VERSION ""

NS_ :

BS_:

BU_: EV EVCC

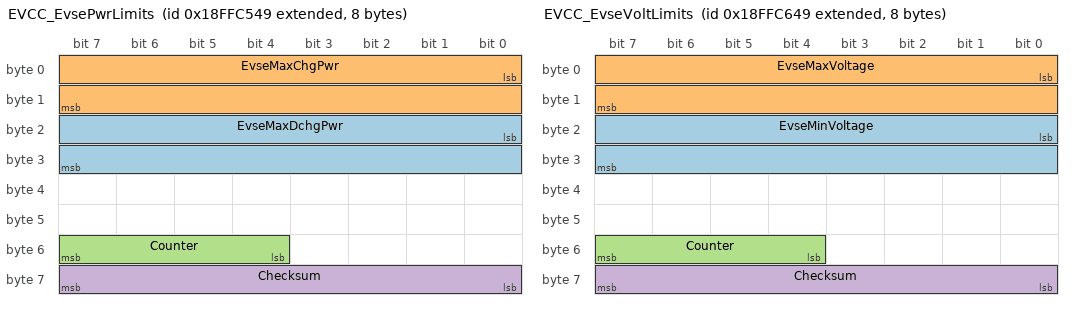
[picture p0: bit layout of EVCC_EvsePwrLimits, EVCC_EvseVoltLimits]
BO_ 2566899017 EVCC_EvsePwrLimits: 8 EVCC
 SG_ EvseMaxDchgPwr : 16|16@1+ (0.5,0) [0|32127.5] "kW"  EV
 SG_ EvseMaxChgPwr : 0|16@1+ (0.5,0) [0|32127.5] "kW"  EV
 SG_ Counter : 52|4@1+ (1,0) [0|0] ""  EV
 SG_ Checksum : 56|8@1+ (1,0) [0|255] "NU"  EV

BO_ 2566899273 EVCC_EvseVoltLimits: 8 EVCC
 SG_ EvseMinVoltage : 16|16@1+ (0.125,0) [0|8031.875] "V"  EV
 SG_ EvseMaxVoltage : 0|16@1+ (0.125,0) [0|8031.875] "V"  EV
 SG_ Counter : 52|4@1+ (1,0) [0|0] ""  EV
 SG_ Checksum : 56|8@1+ (1,0) [0|255] "NU"  EV

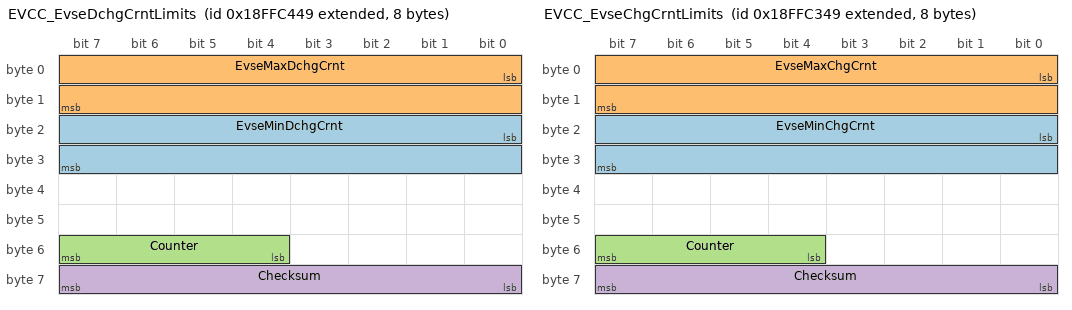
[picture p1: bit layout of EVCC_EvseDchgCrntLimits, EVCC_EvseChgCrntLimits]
BO_ 2566898761 EVCC_EvseDchgCrntLimits: 8 EVCC
 SG_ EvseMinDchgCrnt : 16|16@1+ (0.125,0) [0|8031.875] "A"  EV
 SG_ EvseMaxDchgCrnt : 0|16@1+ (0.125,0) [0|8031.875] "A"  EV
 SG_ Counter : 52|4@1+ (1,0) [0|0] ""  EV
 SG_ Checksum : 56|8@1+ (1,0) [0|255] "NU"  EV

BO_ 2566898505 EVCC_EvseChgCrntLimits: 8 EVCC
 SG_ EvseMinChgCrnt : 16|16@1+ (0.125,0) [0|8031.875] "A"  EV
 SG_ EvseMaxChgCrnt : 0|16@1+ (0.125,0) [0|8031.875] "A"  EV
 SG_ Counter : 52|4@1+ (1,0) [0|0] ""  EV
 SG_ Checksum : 56|8@1+ (1,0) [0|255] "NU"  EV

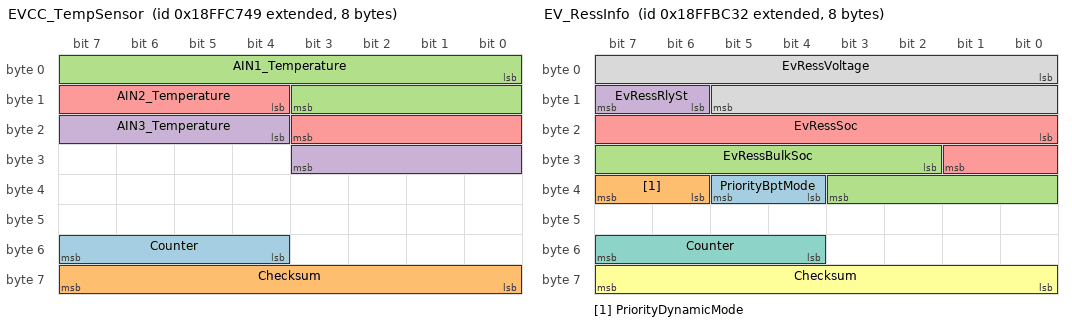
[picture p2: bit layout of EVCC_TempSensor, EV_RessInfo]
BO_ 2566899529 EVCC_TempSensor: 8 EVCC
 SG_ Counter : 52|4@1+ (1,0) [0|0] ""  EV
 SG_ Checksum : 56|8@1+ (1,0) [0|255] "NU"  EV
 SG_ AIN1_Temperature : 0|12@1+ (1,-40) [-40|4000] "degC_or_Ohm"  EV
 SG_ AIN3_Temperature : 20|8@1+ (1,-40) [-40|210] "degC"  EV
 SG_ AIN2_Temperature : 12|8@1+ (1,-40) [-40|210] "degC"  EV

BO_ 2566896690 EV_RessInfo: 8 EV
 SG_ PriorityBptMode : 36|2@1+ (1,0) [0|3] ""  EVCC
 SG_ PriorityDynamicMode : 38|2@1+ (1,0) [0|3] ""  EVCC
 SG_ EvRessBulkSoc : 26|10@1+ (0.1,0) [0|100] "%"  EVCC
 SG_ EvRessRlySt : 14|2@1+ (1,0) [0|3] "bool"  EVCC
 SG_ EvRessSoc : 16|10@1+ (0.1,0) [0|100] "%"  EVCC
 SG_ Checksum : 56|8@1+ (1,0) [0|255] "NU"  EVCC
 SG_ Counter : 52|4@1+ (1,0) [0|0] ""  EVCC
 SG_ EvRessVoltage : 0|14@1+ (0.1,0) [0|1638.3] "V"  EVCC

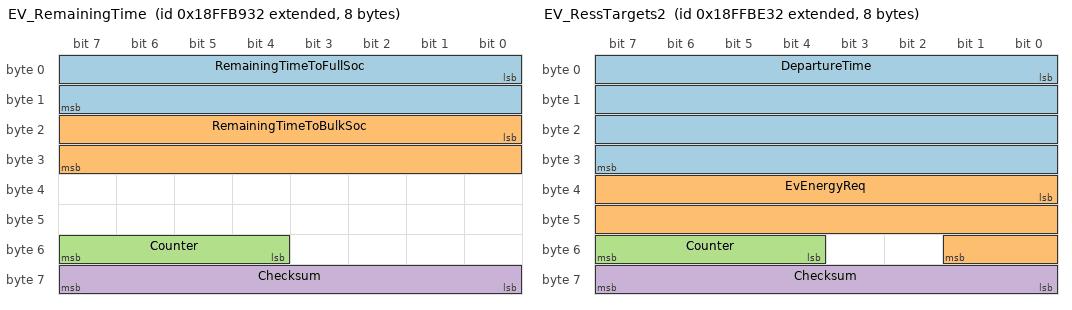
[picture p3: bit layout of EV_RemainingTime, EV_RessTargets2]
BO_ 2566895922 EV_RemainingTime: 8 EV
 SG_ RemainingTimeToFullSoc : 0|16@1+ (5,0) [0|327675] "s"  EVCC
 SG_ RemainingTimeToBulkSoc : 16|16@1+ (5,0) [0|327675] "s"  EVCC
 SG_ Counter : 52|4@1+ (1,0) [0|0] ""  EVCC
 SG_ Checksum : 56|8@1+ (1,0) [0|255] "NU"  EVCC

BO_ 2566897202 EV_RessTargets2: 8 EV
 SG_ DepartureTime : 0|32@1+ (1,0) [0|4294967295] "s"  EVCC
 SG_ EvEnergyReq : 32|18@1- (0.5,0) [-65536|65535.5] "kWh"  EVCC
 SG_ Counter : 52|4@1+ (1,0) [0|0] ""  EVCC
 SG_ Checksum : 56|8@1+ (1,0) [0|255] "NU"  EVCC

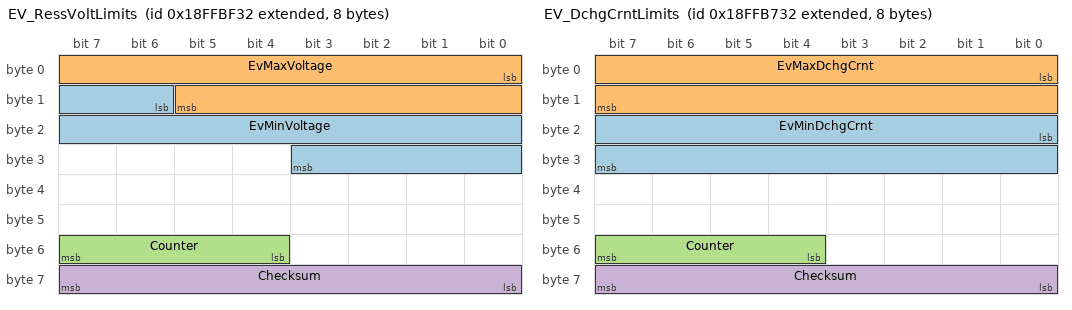
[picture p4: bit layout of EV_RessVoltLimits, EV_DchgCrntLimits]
BO_ 2566897458 EV_RessVoltLimits: 8 EV
 SG_ EvMinVoltage : 14|14@1+ (0.1,0) [0|1638.3] "V"  EVCC
 SG_ EvMaxVoltage : 0|14@1+ (0.1,0) [0|1638.3] "V"  EVCC
 SG_ Counter : 52|4@1+ (1,0) [0|0] ""  EVCC
 SG_ Checksum : 56|8@1+ (1,0) [0|255] "NU"  EVCC

BO_ 2566895410 EV_DchgCrntLimits: 8 EV
 SG_ EvMinDchgCrnt : 16|16@1- (0.1,0) [-3276.8|3276.7] "A"  EVCC
 SG_ EvMaxDchgCrnt : 0|16@1- (0.1,0) [-3276.8|3276.7] "A"  EVCC
 SG_ Counter : 52|4@1+ (1,0) [0|0] ""  EVCC
 SG_ Checksum : 56|8@1+ (1,0) [0|255] "NU"  EVCC

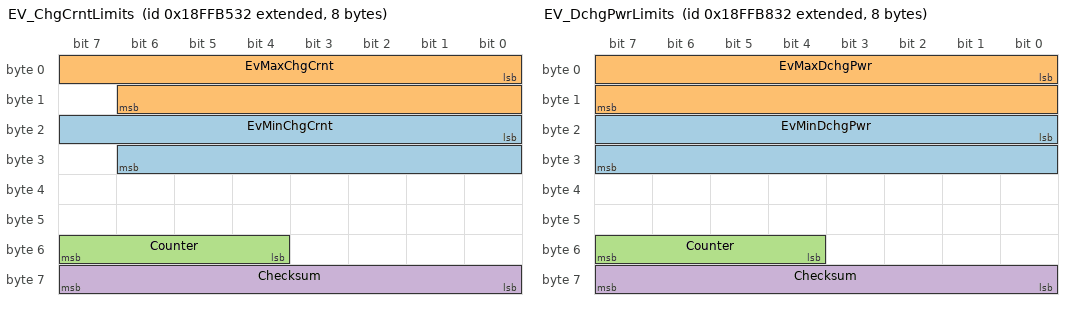
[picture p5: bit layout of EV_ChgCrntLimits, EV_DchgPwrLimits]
BO_ 2566894898 EV_ChgCrntLimits: 8 EV
 SG_ EvMinChgCrnt : 16|15@1+ (0.1,0) [0|3276.7] "A"  EVCC
 SG_ EvMaxChgCrnt : 0|15@1+ (0.1,0) [0|3276.7] "A"  EVCC
 SG_ Counter : 52|4@1+ (1,0) [0|0] ""  EVCC
 SG_ Checksum : 56|8@1+ (1,0) [0|255] "NU"  EVCC

BO_ 2566895666 EV_DchgPwrLimits: 8 EV
 SG_ EvMinDchgPwr : 16|16@1- (0.1,0) [-3276.8|3276.7] "kW"  EVCC
 SG_ EvMaxDchgPwr : 0|16@1- (0.1,0) [-3276.8|3276.7] "kW"  EVCC
 SG_ Counter : 52|4@1+ (1,0) [0|0] ""  EVCC
 SG_ Checksum : 56|8@1+ (1,0) [0|255] "NU"  EVCC

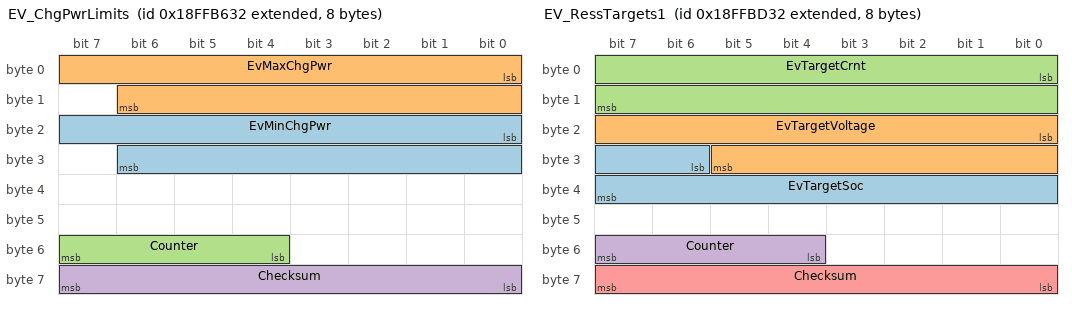
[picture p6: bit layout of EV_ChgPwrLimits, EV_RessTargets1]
BO_ 2566895154 EV_ChgPwrLimits: 8 EV
 SG_ EvMinChgPwr : 16|15@1+ (0.1,0) [0|3276.7] "kW"  EVCC
 SG_ EvMaxChgPwr : 0|15@1+ (0.1,0) [0|3276.7] "kW"  EVCC
 SG_ Counter : 52|4@1+ (1,0) [0|0] ""  EVCC
 SG_ Checksum : 56|8@1+ (1,0) [0|255] "NU"  EVCC

BO_ 2566896946 EV_RessTargets1: 8 EV
 SG_ EvTargetSoc : 30|10@1+ (0.1,0) [0|100] "%"  EVCC
 SG_ EvTargetVoltage : 16|14@1+ (0.1,0) [0|1638.3] "V"  EVCC
 SG_ EvTargetCrnt : 0|16@1- (0.1,0) [-3276.8|3276.7] "A"  EVCC
 SG_ Counter : 52|4@1+ (1,0) [0|0] ""  EVCC
 SG_ Checksum : 56|8@1+ (1,0) [0|255] "NU"  EVCC

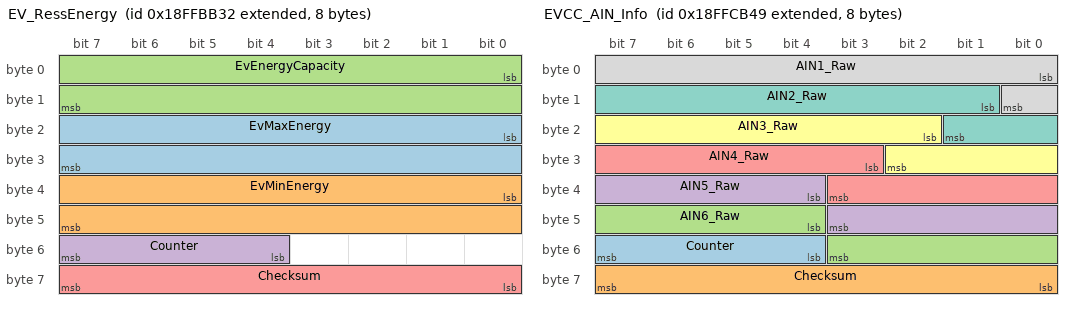
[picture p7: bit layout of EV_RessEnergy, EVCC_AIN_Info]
BO_ 2566896434 EV_RessEnergy: 8 EV
 SG_ EvMaxEnergy : 16|16@1+ (1,0) [0|65535] "kWh"  EVCC
 SG_ EvMinEnergy : 32|16@1+ (1,0) [0|65535] "kWh"  EVCC
 SG_ EvEnergyCapacity : 0|16@1+ (1,0) [0|65535] "kWh"  EVCC
 SG_ Counter : 52|4@1+ (1,0) [0|0] ""  EVCC
 SG_ Checksum : 56|8@1+ (1,0) [0|255] "NU"  EVCC

BO_ 2566900553 EVCC_AIN_Info: 8 EVCC
 SG_ Counter : 52|4@1+ (1,0) [0|0] ""  EV
 SG_ Checksum : 56|8@1+ (1,0) [0|255] "NU"  EV
 SG_ AIN6_Raw : 44|8@1+ (0.02,0) [0|5] "V"  EV
 SG_ AIN5_Raw : 36|8@1+ (0.02,0) [0|5] "V"  EV
 SG_ AIN4_Raw : 27|9@1+ (0.1,0) [0|32] "V"  EV
 SG_ AIN3_Raw : 18|9@1+ (0.01,0) [0|5] "V"  EV
 SG_ AIN2_Raw : 9|9@1+ (0.01,0) [0|5] "V"  EV
 SG_ AIN1_Raw : 0|9@1+ (0.01,0) [0|5] "V"  EV

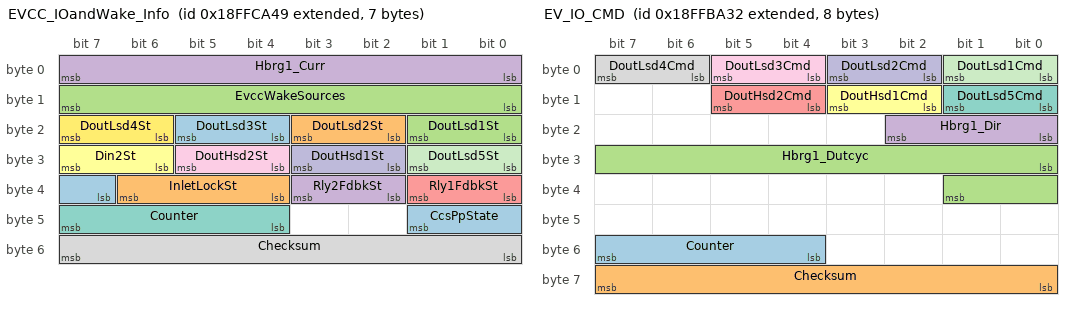
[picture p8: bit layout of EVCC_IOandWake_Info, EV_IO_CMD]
BO_ 2566900297 EVCC_IOandWake_Info: 7 EVCC
 SG_ CcsPpState : 39|3@1+ (1,0) [0|7] ""  EV
 SG_ InletLockSt : 36|3@1+ (1,0) [0|7] ""  EV
 SG_ EvccWakeSources : 8|8@1+ (1,0) [0|255] ""  EV
 SG_ Rly2FdbkSt : 34|2@1+ (1,0) [0|3] "NU"  EV
 SG_ Rly1FdbkSt : 32|2@1+ (1,0) [0|3] "NU"  EV
 SG_ Din2St : 30|2@1+ (1,0) [0|3] "NU"  EV
 SG_ Counter : 44|4@1+ (1,0) [0|0] ""  EV
 SG_ Checksum : 48|8@1+ (1,0) [0|255] "NU"  EV
 SG_ DoutHsd2St : 28|2@1+ (1,0) [0|3] "NU"  EV
 SG_ DoutHsd1St : 26|2@1+ (1,0) [0|3] "NU"  EV
 SG_ DoutLsd5St : 24|2@1+ (1,0) [0|3] "NU"  EV
 SG_ DoutLsd4St : 22|2@1+ (1,0) [0|3] "NU"  EV
 SG_ DoutLsd3St : 20|2@1+ (1,0) [0|3] "NU"  EV
 SG_ DoutLsd2St : 18|2@1+ (1,0) [0|3] "NU"  EV
 SG_ DoutLsd1St : 16|2@1+ (1,0) [0|3] "NU"  EV
 SG_ Hbrg1_Curr : 0|8@1+ (0.1,0) [0|21] "A"  EV

BO_ 2566896178 EV_IO_CMD: 8 EV
 SG_ Counter : 52|4@1+ (1,0) [0|0] ""  EVCC
 SG_ Checksum : 56|8@1+ (1,0) [0|255] "NU"  EVCC
 SG_ Hbrg1_Dutcyc : 24|10@1+ (0.1,0) [0|100] "%"  EVCC
 SG_ Hbrg1_Dir : 16|3@1+ (1,0) [0|7] "NU"  EVCC
 SG_ DoutHsd2Cmd : 12|2@1+ (1,0) [0|3] "bool"  EVCC
 SG_ DoutHsd1Cmd : 10|2@1+ (1,0) [0|3] "bool"  EVCC
 SG_ DoutLsd5Cmd : 8|2@1+ (1,0) [0|3] "bool"  EVCC
 SG_ DoutLsd4Cmd : 6|2@1+ (1,0) [0|3] "bool"  EVCC
 SG_ DoutLsd3Cmd : 4|2@1+ (1,0) [0|3] "bool"  EVCC
 SG_ DoutLsd2Cmd : 2|2@1+ (1,0) [0|3] "bool"  EVCC
 SG_ DoutLsd1Cmd : 0|2@1+ (1,0) [0|3] "bool"  EVCC

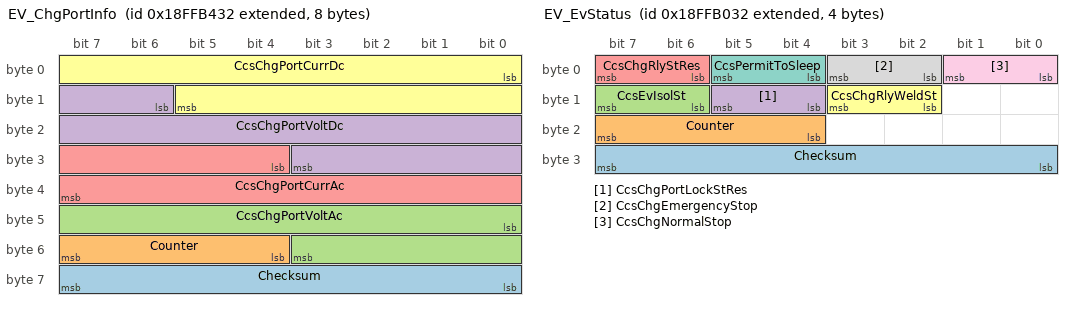
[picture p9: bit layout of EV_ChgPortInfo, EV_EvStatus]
BO_ 2566894642 EV_ChgPortInfo: 8 EV
 SG_ Checksum : 56|8@1+ (1,0) [0|255] "NU"  EVCC
 SG_ Counter : 52|4@1+ (1,0) [0|0] ""  EVCC
 SG_ CcsChgPortVoltAc : 40|12@1+ (0.1,0) [0|409.5] "V"  EVCC
 SG_ CcsChgPortVoltDc : 14|14@1+ (0.1,0) [0|1638.3] "V"  EVCC
 SG_ CcsChgPortCurrAc : 28|12@1+ (0.1,0) [0|409.5] "A"  EVCC
 SG_ CcsChgPortCurrDc : 0|14@1- (0.1,0) [-819.2|819.1] "A"  EVCC

BO_ 2566893618 EV_EvStatus: 4 EV
 SG_ Checksum : 24|8@1+ (1,0) [0|255] "NU"  EVCC
 SG_ Counter : 20|4@1+ (1,0) [0|0] ""  EVCC
 SG_ CcsEvIsolSt : 14|2@1+ (1,0) [0|3] "bool"  EVCC
 SG_ CcsChgPortLockStRes : 12|2@1+ (1,0) [0|3] "bool"  EVCC
 SG_ CcsChgRlyStRes : 6|2@1+ (1,0) [0|3] "bool"  EVCC
 SG_ CcsChgRlyWeldSt : 10|2@1+ (1,0) [0|3] "bool"  EVCC
 SG_ CcsPermitToSleep : 4|2@1+ (1,0) [0|3] "bool"  EVCC
 SG_ CcsChgEmergencyStop : 2|2@1+ (1,0) [0|3] "bool"  EVCC
 SG_ CcsChgNormalStop : 0|2@1+ (1,0) [0|3] "bool"  EVCC

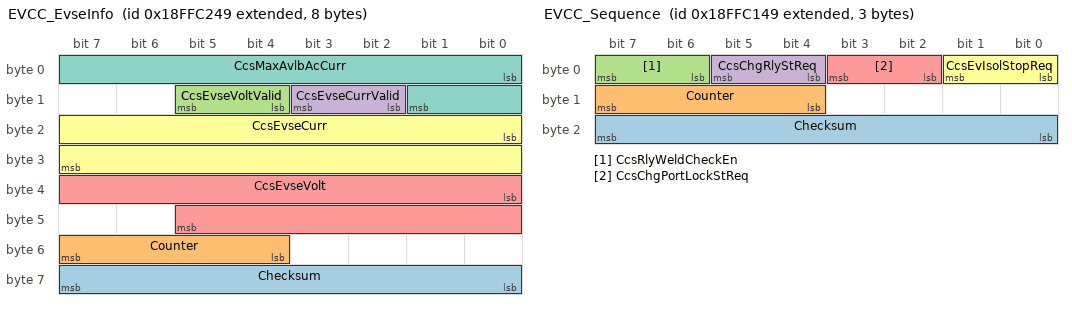
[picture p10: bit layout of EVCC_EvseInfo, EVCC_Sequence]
BO_ 2566898249 EVCC_EvseInfo: 8 EVCC
 SG_ Checksum : 56|8@1+ (1,0) [0|255] "NU"  EV
 SG_ Counter : 52|4@1+ (1,0) [0|0] ""  EV
 SG_ CcsEvseVoltValid : 12|2@1+ (1,0) [0|3] "bool"  EV
 SG_ CcsEvseCurrValid : 10|2@1+ (1,0) [0|3] "bool"  EV
 SG_ CcsEvseVolt : 32|14@1+ (0.1,0) [0|1638.3] "V"  EV
 SG_ CcsEvseCurr : 16|16@1- (0.1,0) [-3276.8|3276.7] "A"  EV
 SG_ CcsMaxAvlbAcCurr : 0|10@1+ (0.1,0) [0|102.3] "A"  EV

BO_ 2566897993 EVCC_Sequence: 3 EVCC
 SG_ Checksum : 16|8@1+ (1,0) [0|255] "NU"  EV
 SG_ Counter : 12|4@1+ (1,0) [0|0] ""  EV
 SG_ CcsRlyWeldCheckEn : 6|2@1+ (1,0) [0|3] "bool"  EV
 SG_ CcsChgRlyStReq : 4|2@1+ (1,0) [0|3] "bool"  EV
 SG_ CcsChgPortLockStReq : 2|2@1+ (1,0) [0|3] "bool"  EV
 SG_ CcsEvIsolStopReq : 0|2@1+ (1,0) [0|3] "bool"  EV

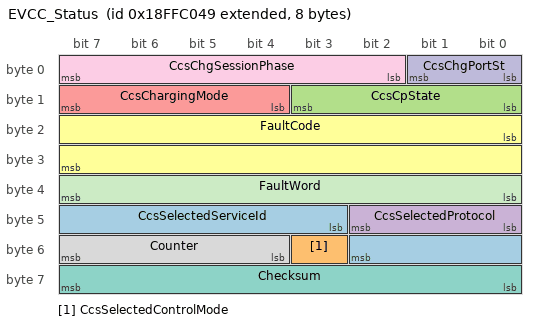
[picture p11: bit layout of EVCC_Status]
BO_ 2566897737 EVCC_Status: 8 EVCC
 SG_ CcsSelectedServiceId : 43|8@1+ (1,0) [0|255] ""  EV
 SG_ CcsSelectedControlMode : 51|1@1+ (1,0) [0|1] ""  EV
 SG_ CcsCpState : 8|4@1+ (1,0) [0|15] ""  EV
 SG_ CcsSelectedProtocol : 40|3@1+ (1,0) [0|7] ""  EV
 SG_ CcsChargingMode : 12|4@1+ (1,0) [0|15] ""  EV
 SG_ FaultCode : 16|16@1+ (1,0) [0|65535] "NU"  EV
 SG_ Checksum : 56|8@1+ (1,0) [0|255] "NU"  EV
 SG_ Counter : 52|4@1+ (1,0) [0|0] ""  EV
 SG_ CcsChgSessionPhase : 2|6@1+ (1,0) [0|63] "No Unit"  EV
 SG_ CcsChgPortSt : 0|2@1+ (1,0) [0|3] "enum"  EV
 SG_ FaultWord : 32|8@1+ (1,0) [0|255] "NU"  EV

CM_ SG_ 2566899017 EvseMaxDchgPwr "Maximum discharge power that the EVSE can deliver";
CM_ SG_ 2566899017 EvseMaxChgPwr "Maximum charge power the EVSE can deliver";
CM_ SG_ 2566899017 Counter "CAN message sequence counter";
CM_ SG_ 2566899017 Checksum "CAN message checksum";
CM_ SG_ 2566899273 EvseMinVoltage "Minimum voltage the EVSE can deliver";
CM_ SG_ 2566899273 EvseMaxVoltage "Maximum voltage the EVSE can deliver";
CM_ SG_ 2566899273 Counter "CAN message sequence counter";
CM_ SG_ 2566899273 Checksum "CAN message checksum";
CM_ SG_ 2566898761 EvseMinDchgCrnt "Minimum discharge current the EVSE can deliver with expected accuracy";
CM_ SG_ 2566898761 EvseMaxDchgCrnt "Maximum discharge current that the EVSE can deliver";
CM_ SG_ 2566898761 Counter "CAN message sequence counter";
CM_ SG_ 2566898761 Checksum "CAN message checksum";
CM_ SG_ 2566898505 EvseMinChgCrnt "Minimum charge current the EVSE can deliver with expected accuracy";
CM_ SG_ 2566898505 EvseMaxChgCrnt "Maximum charge current the EVSE can deliver";
CM_ SG_ 2566898505 Counter "CAN message sequence counter";
CM_ SG_ 2566898505 Checksum "CAN message checksum";
CM_ SG_ 2566899529 Counter "CAN message sequence counter";
CM_ SG_ 2566899529 Checksum "CAN message checksum";
CM_ SG_ 2566899529 AIN1_Temperature "Temperature measured using AIN1; Typically AC pin temperature at charge inlet; Value can be in Ohm (PTC) or degC (other types such as PT1000, NTC, etc.)";
CM_ SG_ 2566899529 AIN3_Temperature "Temperature measured using AIN3; Typically DC negative pin temperature at charge inlet";
CM_ SG_ 2566899529 AIN2_Temperature "Temperature measured using AIN 2; Typically DC positive pin temperature at charge inlet";
CM_ SG_ 2566896690 PriorityBptMode "Priority for BPT mode";
CM_ SG_ 2566896690 PriorityDynamicMode "Priority for dynamic mode";
CM_ SG_ 2566896690 EvRessBulkSoc "Value of RESS BULK State of charge (SOC); Communicated to EVSE for display/ information purpose only.";
CM_ SG_ 2566896690 EvRessRlySt "TRUE value is a verification from EV that the HV charge relay(s) at the RESS terminal are closed.";
CM_ SG_ 2566896690 EvRessSoc "Present value of RESS State of charge (SOC)";
CM_ SG_ 2566896690 Checksum "CAN message checksumCAN message checksum";
CM_ SG_ 2566896690 Counter "CAN message sequence counter";
CM_ SG_ 2566896690 EvRessVoltage "Present value of RESS voltage";
CM_ SG_ 2566895922 RemainingTimeToFullSoc "Remaining time to Full/ Target SOC calculated by VCU (for display and information to EVSE)";
CM_ SG_ 2566895922 RemainingTimeToBulkSoc "Remaining time to Bulk SOC calculated by VCU (for display and information to EVSE)";
CM_ SG_ 2566895922 Counter "CAN message sequence counter";
CM_ SG_ 2566895922 Checksum "CAN message checksumCAN message checksum";
CM_ SG_ 2566897202 DepartureTime "Time used to indicate when the vehicle intends to finish the charge process. Offset in seconds from the point in time the message with DepartureTime is sent by EVCC";
CM_ SG_ 2566897202 EvEnergyReq "Energy request during charge/ discharge session";
CM_ SG_ 2566897202 Counter "CAN message sequence counter";
CM_ SG_ 2566897202 Checksum "CAN message checksumCAN message checksum";
CM_ SG_ 2566897458 EvMinVoltage "The minimum allowable voltage of RESS";
CM_ SG_ 2566897458 EvMaxVoltage "The maximum allowable voltage of RESS";
CM_ SG_ 2566897458 Counter "CAN message sequence counter";
CM_ SG_ 2566897458 Checksum "CAN message checksumCAN message checksum";
CM_ SG_ 2566895410 EvMinDchgCrnt "The minimum allowable discharging current of RESS at each moment";
CM_ SG_ 2566895410 EvMaxDchgCrnt "The maximum allowable discharging current of RESS at each moment";
CM_ SG_ 2566895410 Counter "CAN message sequence counter";
CM_ SG_ 2566895410 Checksum "CAN message checksumCAN message checksum";
CM_ SG_ 2566894898 EvMinChgCrnt "The minimum allowable charging current of RESS at each moment";
CM_ SG_ 2566894898 EvMaxChgCrnt "The maximum allowable charging current of RESS at each moment";
CM_ SG_ 2566894898 Counter "CAN message sequence counter";
CM_ SG_ 2566894898 Checksum "CAN message checksumCAN message checksum";
CM_ SG_ 2566895666 EvMinDchgPwr "The minimum allowable discharging power of RESS";
CM_ SG_ 2566895666 EvMaxDchgPwr "The maximum allowable discharging power of RESS";
CM_ SG_ 2566895666 Counter "CAN message sequence counter";
CM_ SG_ 2566895666 Checksum "CAN message checksumCAN message checksum";
CM_ SG_ 2566895154 EvMinChgPwr "The minimum allowable charging power of RESS";
CM_ SG_ 2566895154 EvMaxChgPwr "The maximum allowable charging power of RESS";
CM_ SG_ 2566895154 Counter "CAN message sequence counter";
CM_ SG_ 2566895154 Checksum "CAN message checksumCAN message checksum";
CM_ SG_ 2566896946 EvTargetSoc "The desired target SOC of RESS at which the charging/ discharging session will stop normally once the signal ‘CcsRessSoc’ reaches this value.";
CM_ SG_ 2566896946 EvTargetVoltage "Target voltage value during charge/ discharge session";
CM_ SG_ 2566896946 EvTargetCrnt "Target current value during charge/ discharge session";
CM_ SG_ 2566896946 Counter "CAN message sequence counter";
CM_ SG_ 2566896946 Checksum "CAN message checksumCAN message checksum";
CM_ SG_ 2566896434 EvMaxEnergy "Maximum energy of battery during charge/ discharge session";
CM_ SG_ 2566896434 EvMinEnergy "Minimum energy of battery during charge/ discharge session";
CM_ SG_ 2566896434 EvEnergyCapacity "Energy capacity of the battery";
CM_ SG_ 2566896434 Counter "CAN message sequence counter";
CM_ SG_ 2566896434 Checksum "CAN message checksumCAN message checksum";
CM_ SG_ 2566900553 Counter "CAN message sequence counter";
CM_ SG_ 2566900553 Checksum "CAN message checksum";
CM_ SG_ 2566900553 AIN6_Raw "The measured raw voltage at Analog input 6";
CM_ SG_ 2566900553 AIN5_Raw "The measured raw voltage at Analog input 5";
CM_ SG_ 2566900553 AIN4_Raw "The measured raw voltage at Analog input 4";
CM_ SG_ 2566900553 AIN3_Raw "The measured raw voltage at Analog input 3";
CM_ SG_ 2566900553 AIN2_Raw "The measured raw voltage at Analog input 2";
CM_ SG_ 2566900553 AIN1_Raw "The measured raw voltage at Analog input 1";
CM_ SG_ 2566900297 CcsPpState "State of Proximity (PP) signal";
CM_ SG_ 2566900297 InletLockSt "State of the inlet lock";
CM_ SG_ 2566900297 EvccWakeSources "Wake sources currently detected by EVCC (bit position based, multiple active possible)
Bit 0: Internal PSU-hold enabled
Bit 1: RTC trigger wake
Bit 2: Ignition asserted
Bit 3: EVSE connected
Bit 4: Selective Wake-on-CAN message wake trigger ";
CM_ SG_ 2566900297 Rly2FdbkSt "Present state of feedback from charge relay/ contactor 2";
CM_ SG_ 2566900297 Rly1FdbkSt "Present state of feedback from charge relay/ contactor 1";
CM_ SG_ 2566900297 Din2St "The present state of digital input 2";
CM_ SG_ 2566900297 Counter "CAN message sequence counter";
CM_ SG_ 2566900297 Checksum "CAN message checksum";
CM_ SG_ 2566900297 DoutHsd2St "The present state of HSD digital output 2";
CM_ SG_ 2566900297 DoutHsd1St "The present state of HSD digital output 1";
CM_ SG_ 2566900297 DoutLsd5St "The present state of LSD digital output 5";
CM_ SG_ 2566900297 DoutLsd4St "The present state of LSD digital output 4";
CM_ SG_ 2566900297 DoutLsd3St "The present state of LSD digital output 3";
CM_ SG_ 2566900297 DoutLsd2St "The present state of LSD digital output 2";
CM_ SG_ 2566900297 DoutLsd1St "The present state of LSD digital output 1";
CM_ SG_ 2566900297 Hbrg1_Curr "estimated current of H-Bridge 1";
CM_ SG_ 2566896178 Counter "CAN message sequence counter";
CM_ SG_ 2566896178 Checksum "CAN message checksum";
CM_ SG_ 2566896178 Hbrg1_Dutcyc "The desired dutycycle of H-Bridge 1";
CM_ SG_ 2566896178 Hbrg1_Dir "The desired direction of H-Bridge 1";
CM_ SG_ 2566896178 DoutHsd2Cmd "The desired state of HSD digital output 2";
CM_ SG_ 2566896178 DoutHsd1Cmd "The desired state of HSD digital output 1";
CM_ SG_ 2566896178 DoutLsd5Cmd "The desired state of LSD digital output 5";
CM_ SG_ 2566896178 DoutLsd4Cmd "The desired state of LSD digital output 4";
CM_ SG_ 2566896178 DoutLsd3Cmd "The desired state of LSD digital output 3";
CM_ SG_ 2566896178 DoutLsd2Cmd "The desired state of LSD digital output 2";
CM_ SG_ 2566896178 DoutLsd1Cmd "The desired state of LSD digital output 1";
CM_ SG_ 2566894642 Checksum "CAN message checksum";
CM_ SG_ 2566894642 Counter "CAN message sequence counter";
CM_ SG_ 2566894642 CcsChgPortVoltAc "AC voltage measured by EV at the charge inlet";
CM_ SG_ 2566894642 CcsChgPortVoltDc "DC voltage measured by EV at the charge inlet (if available)";
CM_ SG_ 2566894642 CcsChgPortCurrAc "AC current measured by EV at the charge inlet";
CM_ SG_ 2566894642 CcsChgPortCurrDc "DC current measured by EV at the charge inlet (if available)";
CM_ SG_ 2566893618 Checksum "CAN message checksum";
CM_ SG_ 2566893618 Counter "CAN message sequence counter";
CM_ SG_ 2566893618 CcsEvIsolSt "TRUE value means EV has stopped HV isolation monitoring";
CM_ SG_ 2566893618 CcsChgPortLockStRes "Current status of charge port lock. TRUE value means locked; FALSE value means unlocked";
CM_ SG_ 2566893618 CcsChgRlyStRes "TRUE value is a verification from EV that the HV charge relay(s) at the charge inlet port are closed.";
CM_ SG_ 2566893618 CcsChgRlyWeldSt "Status of relay weld-checking operation for the HV charging relays; 1 means EV has completed weld checking, 0 means incomplete";
CM_ SG_ 2566893618 CcsPermitToSleep "TRUE: Permission from EV for PI-EVCC to go to sleep mode (is ignored during an ongoing charging session)";
CM_ SG_ 2566893618 CcsChgEmergencyStop "FALSE: Permission from EV to Start Charging; TRUE: Permission to start charging denied or a request from EV to immediately stop an ongoing charging session";
CM_ SG_ 2566893618 CcsChgNormalStop "FALSE: Permission from EV to Start Charging; TRUE: Permission to start charging denied or a request from EV to normally stop an ongoing charging session";
CM_ SG_ 2566898249 Checksum "CAN message checksum";
CM_ SG_ 2566898249 Counter "CAN message sequence counter";
CM_ SG_ 2566898249 CcsEvseVoltValid "TRUE value indicates the value of CAN signal ‘CcsEvseVolt’ is valid, i.e., the measurement has been updated during the last 400ms.";
CM_ SG_ 2566898249 CcsEvseCurrValid "TRUE value indicates the value of CAN signal ‘CcsEvseCurr’ is valid, i.e., the measurement has been updated during the last 200ms.";
CM_ SG_ 2566898249 CcsEvseVolt "The charging DC voltage measured by EVSE at the charge port";
CM_ SG_ 2566898249 CcsEvseCurr "The charging DC current measured by EVSE at the charge port";
CM_ SG_ 2566898249 CcsMaxAvlbAcCurr "The maximum available AC current that EV is allowed to draw from EVSE";
CM_ SG_ 2566897993 Checksum "CAN message checksum";
CM_ SG_ 2566897993 Counter "CAN message sequence counter";
CM_ SG_ 2566897993 CcsRlyWeldCheckEn "Charging session sequence of events: TRUE value is to notify EV that the logic for relay weld-checking can be executed";
CM_ SG_ 2566897993 CcsChgRlyStReq "Desired relay status request from PI-EVCC; TRUE value is a request to close the relay;";
CM_ SG_ 2566897993 CcsChgPortLockStReq "Desired status of charge port lock. TRUE value is a request to lock the port and FALSE value is a request to unlock it";
CM_ SG_ 2566897993 CcsEvIsolStopReq "TRUE value is a Request from PI-EVCC for EV to stop HV Isolation monitoring";
CM_ SG_ 2566897737 CcsSelectedServiceId "Service ID selected during an HLC session; DC_Charging (2), DC_BPT (17)";
CM_ SG_ 2566897737 CcsSelectedControlMode "Control Mode selected during ISO15118-20 HLC session; 1 = Dynamic control mode, 0 = Schedule control mode";
CM_ SG_ 2566897737 CcsCpState "State of Control Pilot (CP) signal";
CM_ SG_ 2566897737 CcsSelectedProtocol "Protocol selected after exchanging SupportedAppProtocolReq/Res pair";
CM_ SG_ 2566897737 CcsChargingMode "Charging mode identified by EVCC based on Control Pilot (CP) PWM input";
CM_ SG_ 2566897737 FaultCode "A code that indicates the presence of an active fault related to communication with EV or PiEVCC pins or any fault that is not directly related to EVSE interface";
CM_ SG_ 2566897737 Checksum "CAN message checksum";
CM_ SG_ 2566897737 Counter "CAN message sequence counter";
CM_ SG_ 2566897737 CcsChgSessionPhase "a number that indicates the current phase of charging session as well as charging mode (AC or DC). See user guide document to interpret the number";
CM_ SG_ 2566897737 CcsChgPortSt "The status of charging port (plugged, unplugged, unknown).";
CM_ SG_ 2566897737 FaultWord "Fault word with each bit representing a particular type of fault";
BA_DEF_ SG_  "SigType" ENUM  "Default","Range","RangeSigned","ASCII","Discrete","Control","ReferencePGN","DTC","StringDelimiter","StringLength","StringLengthControl","MessageCounter","MessageChecksum";
BA_DEF_ SG_  "GenSigEVName" STRING ;
BA_DEF_ SG_  "GenSigILSupport" ENUM  "No","Yes";
BA_DEF_ SG_  "GenSigSendType" ENUM  "Cyclic","OnWrite","OnWriteWithRepetition","OnChange","OnChangeWithRepetition","IfActive","IfActiveWithRepetition","NoSigSendType";
BA_DEF_ SG_  "GenSigStartValue" INT 0 10000;
BA_DEF_ BO_  "GenMsgILSupport" ENUM  "No","Yes";
BA_DEF_ BU_  "NmStationAddress" INT 0 255;
BA_DEF_ BO_  "GenMsgSendType" ENUM  "cyclic","NotUsed","IfActive","NotUsed","NotUsed","NotUsed","NotUsed","NotUsed","noMsgSendType";
BA_DEF_ BO_  "GenMsgRequestable" INT 0 1;
BA_DEF_ BO_  "GenMsgCycleTime" INT 0 3600000;
BA_DEF_  "DBName" STRING ;
BA_DEF_  "BusType" STRING ;
BA_DEF_  "ProtocolType" STRING ;
BA_DEF_ BO_  "VFrameFormat" ENUM  "StandardCAN","ExtendedCAN","reserved","J1939PG";
BA_DEF_DEF_  "SigType" "Default";
BA_DEF_DEF_  "GenSigEVName" "Env@Nodename_@Signame";
BA_DEF_DEF_  "GenSigILSupport" "Yes";
BA_DEF_DEF_  "GenSigSendType" "NoSigSendType";
BA_DEF_DEF_  "GenSigStartValue" 0;
BA_DEF_DEF_  "GenMsgILSupport" "Yes";
BA_DEF_DEF_  "NmStationAddress" 254;
BA_DEF_DEF_  "GenMsgSendType" "noMsgSendType";
BA_DEF_DEF_  "GenMsgRequestable" 1;
BA_DEF_DEF_  "GenMsgCycleTime" 0;
BA_DEF_DEF_  "DBName" "";
BA_DEF_DEF_  "BusType" "CAN";
BA_DEF_DEF_  "ProtocolType" "J1939";
BA_DEF_DEF_  "VFrameFormat" "J1939PG";
BA_ "DBName" "PiEVCC_VehicleBus";
BA_ "NmStationAddress" BU_ EV 50;
BA_ "NmStationAddress" BU_ EVCC 73;
BA_ "GenMsgSendType" BO_ 2566899017 0;
BA_ "GenMsgCycleTime" BO_ 2566899017 100;
BA_ "GenMsgSendType" BO_ 2566899273 0;
BA_ "GenMsgCycleTime" BO_ 2566899273 100;
BA_ "GenMsgSendType" BO_ 2566898761 0;
BA_ "GenMsgCycleTime" BO_ 2566898761 100;
BA_ "GenMsgSendType" BO_ 2566898505 0;
BA_ "GenMsgCycleTime" BO_ 2566898505 100;
BA_ "GenMsgSendType" BO_ 2566899529 0;
BA_ "GenMsgCycleTime" BO_ 2566899529 500;
BA_ "GenMsgSendType" BO_ 2566896690 0;
BA_ "GenMsgCycleTime" BO_ 2566896690 100;
BA_ "GenMsgSendType" BO_ 2566895922 0;
BA_ "GenMsgCycleTime" BO_ 2566895922 250;
BA_ "GenMsgSendType" BO_ 2566897202 0;
BA_ "GenMsgCycleTime" BO_ 2566897202 20;
BA_ "GenMsgSendType" BO_ 2566897458 0;
BA_ "GenMsgCycleTime" BO_ 2566897458 100;
BA_ "GenMsgSendType" BO_ 2566895410 0;
BA_ "GenMsgCycleTime" BO_ 2566895410 100;
BA_ "GenMsgSendType" BO_ 2566894898 0;
BA_ "GenMsgCycleTime" BO_ 2566894898 100;
BA_ "GenMsgSendType" BO_ 2566895666 0;
BA_ "GenMsgCycleTime" BO_ 2566895666 100;
BA_ "GenMsgSendType" BO_ 2566895154 0;
BA_ "GenMsgCycleTime" BO_ 2566895154 100;
BA_ "GenMsgSendType" BO_ 2566896946 0;
BA_ "GenMsgCycleTime" BO_ 2566896946 20;
BA_ "GenMsgSendType" BO_ 2566896434 0;
BA_ "GenMsgCycleTime" BO_ 2566896434 100;
BA_ "GenMsgSendType" BO_ 2566900553 0;
BA_ "GenMsgCycleTime" BO_ 2566900553 20;
BA_ "GenMsgCycleTime" BO_ 2566900297 20;
BA_ "GenMsgSendType" BO_ 2566900297 0;
BA_ "GenMsgCycleTime" BO_ 2566896178 100;
BA_ "GenMsgSendType" BO_ 2566896178 0;
BA_ "GenMsgCycleTime" BO_ 2566894642 100;
BA_ "GenMsgSendType" BO_ 2566894642 0;
BA_ "GenMsgCycleTime" BO_ 2566893618 100;
BA_ "GenMsgSendType" BO_ 2566893618 0;
BA_ "GenMsgCycleTime" BO_ 2566898249 100;
BA_ "GenMsgSendType" BO_ 2566898249 0;
BA_ "GenMsgCycleTime" BO_ 2566897993 100;
BA_ "GenMsgSendType" BO_ 2566897993 0;
BA_ "GenMsgCycleTime" BO_ 2566897737 20;
BA_ "GenMsgSendType" BO_ 2566897737 0;
BA_ "GenSigStartValue" SG_ 2566899529 AIN1_Temperature 40;
BA_ "GenSigStartValue" SG_ 2566899529 AIN3_Temperature 40;
BA_ "GenSigStartValue" SG_ 2566899529 AIN2_Temperature 40;
BA_ "GenSigStartValue" SG_ 2566893618 CcsChgEmergencyStop 1;
BA_ "GenSigStartValue" SG_ 2566893618 CcsChgNormalStop 1;
VAL_ 2566896690 PriorityBptMode 3 "Disabled" 2 "Fallback" 1 "Preferred" 0 "Reserved" ;
VAL_ 2566896690 PriorityDynamicMode 3 "Disabled" 2 "Fallback" 1 "Preferred" 0 "Reserved" ;
VAL_ 2566900297 CcsPpState 7 "PROX_INVALID" 6 "PROX_CONNECTED_1500OHM" 5 "PROX_CONNECTED_680OHM" 4 "PROX_CONNECTED_220OHM" 3 "PROX_CONNECTED_100OHM" 2 "PROX_CONNECTED_S3_CLOSE" 1 "PROX_CONNECTED_S3_OPEN" 0 "PROX_DISCONNECTED" ;
VAL_ 2566900297 InletLockSt 7 "SNA" 4 "Error" 3 "Locked" 2 "Unlocked" 1 "Moving" 0 "Unknown" ;
VAL_ 2566900297 Rly2FdbkSt 3 "SNA" 1 "Closed" 0 "Open" ;
VAL_ 2566900297 Rly1FdbkSt 3 "SNA" 1 "Closed" 0 "Open" ;
VAL_ 2566896178 Hbrg1_Dir 3 "Reverse" 2 "Forward" 1 "Brake" 0 "No Drive" ;
VAL_ 2566897737 CcsCpState 9 "PILOT_ST_F_m12V_OSCILTR_OFF" 8 "PILOT_ST_E_0V" 7 "PILOT_ST_D1_3V_OSCILTR_OFF" 6 "PILOT_ST_C1_6V_OSCILTR_OFF" 5 "PILOT_ST_D2_3V_OSCILTR_ON" 4 "PILOT_ST_C2_6V_OSCILTR_ON" 3 "PILOT_ST_B2_9V_OSCILTR_ON" 2 "PILOT_ST_B1_9V_OSCILTR_OFF" 1 "PILOT_ST_A_0V_DISCONNECTED" 0 "PILOT_ST_UNKNOWN" ;
VAL_ 2566897737 CcsSelectedProtocol 2 "ISO 15118-20 (ED2)" 1 "ISO 15118-2 (ED1)" 0 "DIN 70121" ;
VAL_ 2566897737 CcsChargingMode 3 "CHARGINGMODE_ERROR" 2 "CHARGINGMODE_AC" 1 "CHARGINGMODE_DC" 0 "CHARGINGMODE_UNKNOWN" ;
VAL_ 2566897737 CcsChgPortSt 3 "CHARGER_PORT_UNKNOWN" 2 "CHARGER_PLUGGED_HV_PRESENT" 1 "CHARGER_PLUGGED_HV_ABSENT" 0 "CHARGER_UNPLUGGED" ;
